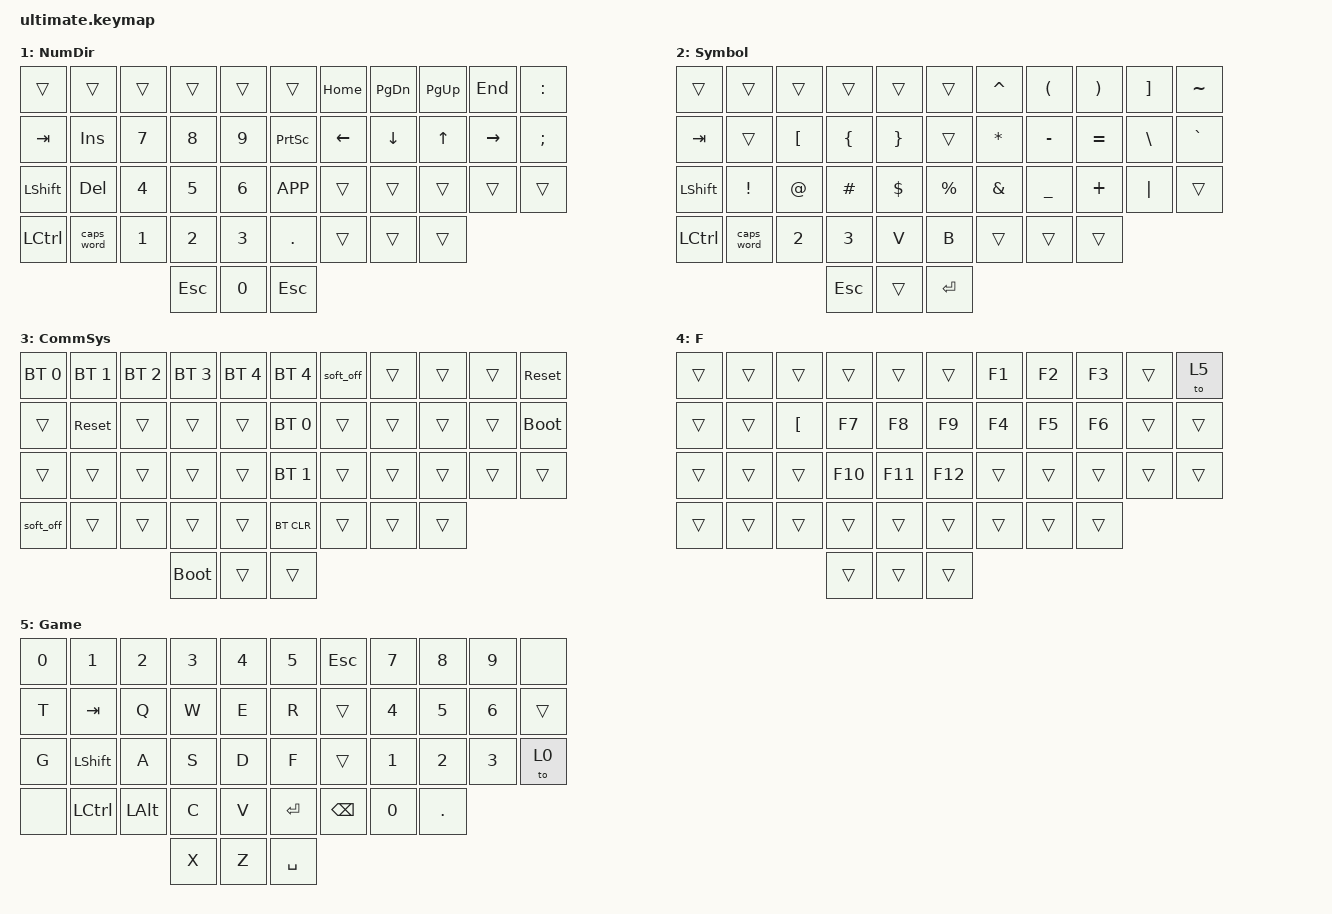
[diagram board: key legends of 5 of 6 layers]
// Copyright (c) 2022 The ZMK Contributors
// SPDX-License-Identifier: MIT

#include <behaviors.dtsi>
#include <dt-bindings/zmk/keys.h>
#include <dt-bindings/zmk/bt.h>

// Home row mods macro
#define HRML(k1,k2,k3,k4) &ht LSHFT k1  &ht LALT k2  &ht LCTRL k3  &ht LGUI k4
#define HRMR(k1,k2,k3,k4) &ht RGUI k1  &ht RCTRL k2  &ht RALT k3  &ht RSHFT k4

/ {
    behaviors {
        ht: hold_tap {
            compatible = "zmk,behavior-hold-tap";
            #binding-cells = <2>;
            flavor = "tap-preferred";
            tapping-term-ms = <220>;
            quick-tap-ms = <150>;
            require-prior-idle-ms = <50>;
            bindings = <&kp>, <&kp>;
        };
    };

    conditional_layers {
        compatible = "zmk,conditional-layers";
        tri_layer {
            if-layers = <1 2>;
            then-layer = <3>;
        };
    };

    keymap {
        compatible = "zmk,keymap";
        default_layer {
            display-name = "Base";
            bindings = <
                //╭──────────┬──────────┬──────────┬──────────┬──────────┬──────────╮   ╭──────────┬──────────┬──────────┬──────────┬──────────╮
                //│  0       │  1       │  2       │  3       │  4       │  5       │   │  Y       │  U       │  I       │  O       │  P       │
                    &kp N0      &kp N1     &kp N2     &kp N3     &kp N4     &kp N5          &kp Y      &kp U      &kp I      &kp O      &kp P
                //├──────────┼──────────┼──────────┼──────────┼──────────├──────────┤   ├──────────┼──────────┼──────────┼──────────┼──────────┤
                //│  TAB     │  Q       │  W       │  E       │  R       │  T       │   │  H       │  J       │  K       │  L       │ ' "      │
                    &kp TAB      &kp Q      &kp W      &kp E      &kp R      &kp T         &kp H      HRMR(J,        K,         L,        SQT)
                //├──────────├──────────┼──────────┼──────────┼──────────┼──────────┤   ├──────────┼──────────┼──────────┼──────────┼──────────┤
                //│  LSHFT   │  A       │  S       │  D       │  F       │  G       │   │  N       │  M       │ , <      │ . >      │ / ?      │
                    &kp LSHFT  HRML(A,        S,         D,         F)      &kp G        &kp N      &kp M      &kp COMMA  &kp DOT    &kp FSLH 
                //├──────────├──────────┼──────────┼──────────┼──────────┼──────────┤   ├──────────┼──────────┼──────────┼──────────┴──────────╯
                //│  LCTRL   │  Z       │  X       │  C       │  V       │  B       │   │ SPACE    │Backspace │ Backspace│
                    &kp LCTRL &kp Z      &kp X      &kp C      &kp V      &kp B          &kp SPACE  &lt 1 BSPC    &kp BSPC
                //╰──────────┴──────────┴──────────┼──────────┼──────────┼──────────┤   ╰──────────┴──────────┴──────────╯
                                                    &kp ESC   &lt 2 TAB   &lt 4 ENTER 
                //                                 ╰──────────┴──────────┴──────────╯   
            >;
        };
        first_layer {
            display-name = "NumDir";
            bindings = <
                //╭──────────┬──────────┬──────────┬──────────┬──────────┬──────────╮   ╭──────────┬──────────┬──────────┬──────────┬──────────╮
                //│  -       │  -       │  -       │  -       │  -       │  -       │   │  HOME    │  PAGE DN │  PAGE UP │  END     │  COLON   │
                    &trans      &trans     &trans     &trans     &trans     &trans        &kp HOME  &kp PG_DN   &kp PG_UP   &kp END   &kp COLON
                //├──────────┼──────────┼──────────┼──────────┼──────────├──────────┤   ├──────────┼──────────┼──────────┼──────────┼──────────┤
                //│  TAB     │  INS     │  7       │  8       │  9       │PRINTSCREN│   │  LEFT    │  DOWN    │  UP      │  RIGHT   │ ;        │
                    &kp TAB      &kp INS   &kp N7      &kp N8    &kp N9    &kp PRINTSCREEN &kp LEFT   &kp DOWN   &kp UP    &kp RIGHT   &kp SEMI
                //├──────────├──────────┼──────────┼──────────┼──────────┼──────────┤   ├──────────┼──────────┼──────────┼──────────┼──────────┤
                //│  LSHFT   │  DELETE  │  4       │  5       │  6       │context m │   │  -       │  -       │   -      │   -      │   -      │
                    &kp LSHFT   &kp DEL      &kp N4   &kp N5      &kp N6  &kp K_APP       &trans     &trans   &trans       &trans    &trans 
                //├──────────├──────────┼──────────┼──────────┼──────────┼──────────┤   ├──────────┼──────────┼──────────┼──────────┴──────────╯
                //│  LCTRL   │  CAPS    │  1       │  2       │  3       │ .        │   │ -        │ -        │ -        │
                    &kp LCTRL &caps_word  &kp N1      &kp N2      &kp N3     &kp DOT         &trans  &trans    &trans
                //╰──────────┴──────────┴──────────┼──────────┼──────────┼──────────┤   ╰──────────┴──────────┴──────────╯
                                                    &kp ESC   &kp N0        &kp ESC 
                //                                 ╰──────────┴──────────┴──────────╯   
            >;
        };
        second_layer {
            display-name = "Symbol";
            bindings = <
                //╭──────────┬──────────┬──────────┬──────────┬──────────┬──────────╮   ╭──────────┬──────────┬──────────┬──────────┬──────────╮
                //│  -       │  -       │  -       │  -       │  -       │  -       │   │  ^       │  (       │  )       │  ]       │  ~       │
                    &trans      &trans     &trans     &trans     &trans     &trans        &kp CARET  &kp LPAR   &kp RPAR   &kp RBKT   &kp TILDE
                //├──────────┼──────────┼──────────┼──────────┼──────────├──────────┤   ├──────────┼──────────┼──────────┼──────────┼──────────┤
                //│  TAB     │          │  [       │  {       │  }       │          │   │  *       │  -       │  =       │  \       │  `       │
                    &kp TAB    &trans     &kp LBKT   &kp LBRC   &kp RBRC   &trans         &kp ASTRK  &kp MINUS  &kp EQUAL  &kp BSLH   &kp GRAVE
                //├──────────├──────────┼──────────┼──────────┼──────────┼──────────┤   ├──────────┼──────────┼──────────┼──────────┼──────────┤
                //│  LSHFT   │  !       │  @       │  #       │  $       │  %       │   │  &       │  _       │  +       │  │       │          │
                    &kp LSHFT  &kp EXCL   &kp AT     &kp HASH   &kp DLLR   &kp PRCNT      &kp AMPS   &kp UNDER  &kp PLUS   &kp PIPE   &trans
                //├──────────├──────────┼──────────┼──────────┼──────────┼──────────┤   ├──────────┼──────────┼──────────┼──────────┴──────────╯
                //│  LCTRL   │  CAPS    │  2       │  3       │  V       │  B       │   │ -        │ -        │ -        │
                    &kp LCTRL &caps_word  &kp 2      &kp 3      &kp V      &kp B          &trans  &trans    &trans
                //╰──────────┴──────────┴──────────┼──────────┼──────────┼──────────┤   ╰──────────┴──────────┴──────────╯
                                                    &kp ESC     &trans     &kp ENTER 
                //                                 ╰──────────┴──────────┴──────────╯   
            >;
        };
        third_layer {
            display-name = "CommSys";
            bindings = <
                //╭─────────────┬────────────┬─────────────┬─────────────┬─────────────┬─────────────╮   ╭──────────┬──────────┬──────────┬──────────┬──────────╮
                //│PROFILE 0    │PROFILE 1   │PROFILE 2    │PROFILE 3    │PROFILE 4    │PROFILE 5    │   │          │          │          │          │  RESET   │
                   &bt BT_SEL 0  &bt BT_SEL 1 &bt BT_SEL 2 &bt BT_SEL 3  &bt BT_SEL 4   &bt BT_SEL 4      &soft_off       &trans   &trans     &trans     &sys_reset
                //├─────────────┼────────────┼─────────────┼─────────────┼─────────────├─────────────┤   ├──────────┼──────────┼──────────┼──────────┼──────────┤
                //│             │ RESET      │             │             │             │PROFILE 0    │   │          │          │          │          │BOOTLOADER│
                    &trans       &sys_reset     &trans       &trans      &trans         &bt BT_SEL 0       &trans     &trans     &trans     &trans    &bootloader
                //├─────────────├────────────┼─────────────┼─────────────┼─────────────┼─────────────┤   ├──────────┼──────────┼──────────┼──────────┼──────────┤
                //│             │            │             │             │             │PROFILE 1    │   │          │          │          │          │          │
                    &trans       &trans       &trans         &trans        &trans        &bt BT_SEL 1      &trans     &trans     &trans     &trans     &trans
                //├─────────────├────────────┼─────────────┼─────────────┼─────────────┼─────────────┤   ├──────────┼──────────┼──────────┼──────────┴──────────╯
                //│  OFF        │            │             │             │             │ CLEAR BT    │   │ -        │ -        │ -        │
                    &soft_off    &trans          &trans          &trans       &trans    &bt BT_CLR       &trans     &trans      &trans
                //╰─────────────┴────────────┴─────────────┼─────────────┼─────────────┼─────────────┤   ╰──────────┴──────────┴──────────╯
                                                            &bootloader    &trans        &trans 
                //                                         ╰─────────────┴─────────────┴─────────────╯   
            >;
        };
        fourth_layer {
            display-name = "F";
            bindings = <
                //╭──────────┬──────────┬──────────┬──────────┬──────────┬──────────╮   ╭──────────┬──────────┬──────────┬──────────┬──────────╮
                //│  -       │  -       │  -       │  -       │  -       │  -       │   │    F1    │    F2    │    F3    │          │  to fith │
                    &trans      &trans     &trans     &trans     &trans     &trans         &kp F1   &kp F2       &kp F3    &trans      &to 5
                //├──────────┼──────────┼──────────┼──────────┼──────────├──────────┤   ├──────────┼──────────┼──────────┼──────────┼──────────┤
                //│          │          │          │    F7    │    F8    │    F9    │   │   F4     │   F5     │    F6    │          │          │
                    &trans     &trans     &kp LBKT    &kp F7     &kp F8     &kp F9         &kp F4     &kp F5     &kp F6     &trans     &trans
                //├──────────├──────────┼──────────┼──────────┼──────────┼──────────┤   ├──────────┼──────────┼──────────┼──────────┼──────────┤
                //│          │          │          │    F10   │   F11    │   F12    │   │          │          │          │          │          │
                    &trans     &trans    &trans     &kp F10     &kp F11    &kp F12       &trans     &trans     &trans   &trans    &trans
                //├──────────├──────────┼──────────┼──────────┼──────────┼──────────┤   ├──────────┼──────────┼──────────┼──────────┴──────────╯
                //│          │          │          │          │          │          │   │ -        │ -        │ -        │
                    &trans      &trans     &trans     &trans      &trans    &trans        &trans    &trans      &trans
                //╰──────────┴──────────┴──────────┼──────────┼──────────┼──────────┤   ╰──────────┴──────────┴──────────╯
                                                    &trans     &trans       &trans 
                //                                 ╰──────────┴──────────┴──────────╯   
            >;
        };
        fith_layer {
            display-name = "Game";
            bindings = <
                //╭──────────┬──────────┬──────────┬──────────┬──────────┬──────────╮   ╭──────────┬────────────┬──────────┬──────────┬──────────╮
                //│  0       │  1       │  2       │  3       │  4       │  5       │   │    ESC   │    7       │  8       │  9       │  nothing │
                    &kp N0      &kp N1     &kp N2     &kp N3     &kp N4     &kp N5          &kp ESC    &kp N7     &kp N8     &kp N9      &none
                //├──────────┼──────────┼──────────┼──────────┼──────────├──────────┤   ├──────────┼────────────┼──────────┼──────────┼──────────┤
                //│     T    │    TAB   │    Q     │    W     │    E     │    R     │   │          │    4       │  5       │  6     
                    &kp T     &kp TAB     &kp Q      &kp W     &kp E       &kp R            &trans    &kp N4     &kp N5     &kp N6    &trans
                //├──────────├──────────┼──────────┼──────────┼──────────┼──────────┤   ├──────────┼────────────┼──────────┼──────────┼──────────┤
                //│    G     │          │     A    │    S     │    D     │     F    │   │          │    1       │  2       │  3       │ Layer 0  │
                    &kp G     &kp LSHFT    &kp A       &kp S    &kp D       &kp F          &trans     &kp N1     &kp N2     &kp N3     &to 0
                //├──────────├──────────┼──────────┼──────────┼──────────┼──────────┤   ├──────────┼────────────┼──────────┼────────────┴──────────╯
                //│          │          │    LALT  │      C   │     V    │   ENTER  │   │ back     │ 0          │ .        │
                    &none     &kp LCTRL  &kp LALT    &kp C     &kp V    &kp ENTER        &kp BSPC     &kp N0      &kp DOT
                //╰──────────┴──────────┴──────────┼──────────┼──────────┼──────────┤   ╰──────────┴────────────┴──────────╯
                                                    &kp X      &kp Z       &kp SPACE
                //                                 ╰──────────┴──────────┴──────────╯   
            >;
        };
    };
};
    
